# GTC0_GTC_CFG1 register map
Vendor: Texas Instruments
Peripheral module from a debugger description file (folder J7VCL).
Registers are 32-bit, read-write, reset 0x0 unless marked. A register's access mark holds for its fields unless they carry their own. Offsets are as the file gives them; lines under a group give offsets from that group; [hi:lo] are bit positions; {n}, {i} and the like mark numbered series; 'fields as' and 'values as' point back to an identical list; <NAME> marks a mode.

## GTC0_GTC_CFG1
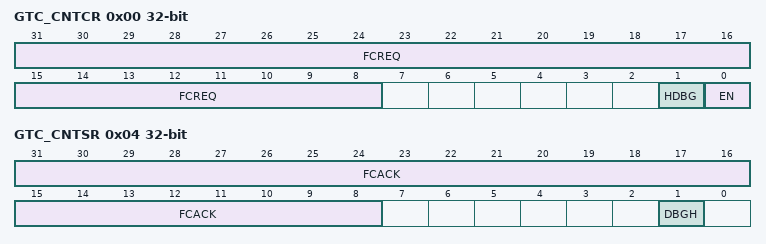
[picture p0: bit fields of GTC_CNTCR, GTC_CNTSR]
0x00 GTC_CNTCR access per field — This register enables the system counter and controls counter operation during debug.
  [31:8] FCREQ ro — Frequency change request. Indicates the number of the entry in the frequency table to select. For this device, this field is implemented as read-only, pointing to the base frequency table entry (000000h).
  [1] HDBG rw — Halt on debug0 = System counter ignores debug halt1 = System counter is halted when debug halt is asserted
  [0] EN rw — Enable system counter0 = System counter is disabled1 = System counter is enabled
0x04 GTC_CNTSR ro (reset mask 0xFFFFFFFD) — This register provides system counter frequency status information.
  [31:8] FCACK — Frequency change ackowledge. Indicates the currently selected entry in the frequency table. For this device, this field is tied to 0.
  [1] DBGH — Debug halt. Indicates if the system counter is halted due to debug.0 = System counter is not halted by a debug halt1 = System counter is halted by a debug halt
0x08 GTC_CNTCV_LO — Indicates the current system counter count value and can be used to set the system counter count value.
  [31:0] COUNTVALUE — Indicates bits [31:0] of the system counter value. This field is only writable when the system counter is disabled. The read value is the current value of system counter count [31:0].
0x0C GTC_CNTCV_HI — Indicates the current system counter count value and can be used to set the system counter count value.
  [31:0] COUNTVALUE — Indicates bits [63:32] of the system counter value. This field is only writable when the system counter is disabled. The read value is the current value of system counter count [63:32].
0x20 GTC_CNTFID0 — Indicates base frequency of the system counter. Device bootcode/firmware should write this register with the frequency of the selected GTC clock source before enabling the system counter.
  [31:0] FREQVALUE — Indicates the base update frequency of the system counter in Hz.
0x24 GTC_CNTFID1 ro — Indicates the system counter increment frequency.
  [31:0] FREQVALUE — Frequency table end indicator. All 0s value marks the end of the frequency table.
